# SF32LB57x register map
File version: 1.0
CPU: CM33 r0p1, little endian, MPU, FPU, 3 interrupt priority bits
Registers are 32-bit, read-write, reset 0x0 unless marked. A register's access mark holds for its fields unless they carry their own. Offsets are from the block's base; [hi:lo] are bit positions; {n}, {i} and the like mark numbered series; 'fields as' and 'values as' point back to an identical list.

## USBC
Base 0x50047000
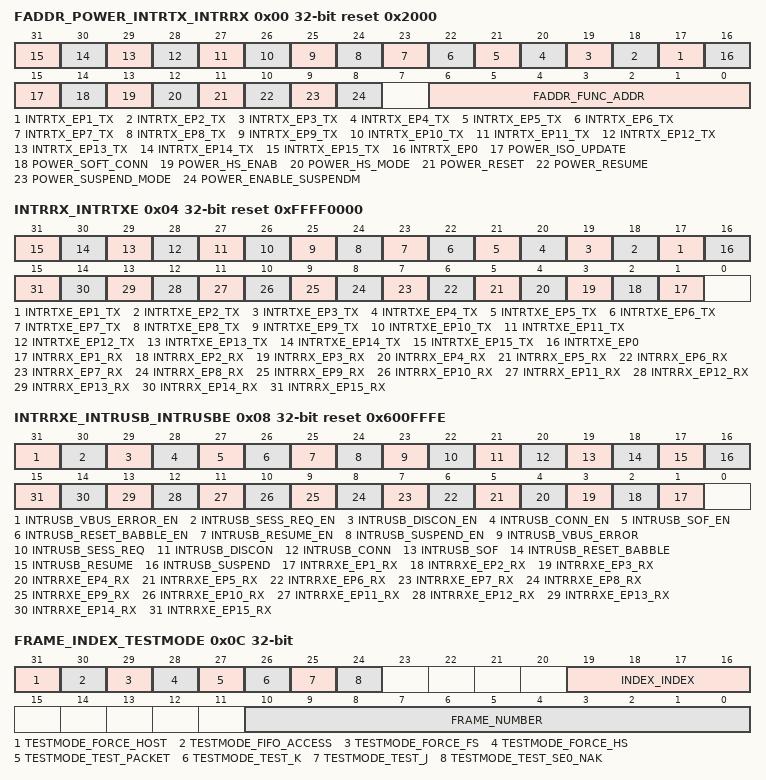
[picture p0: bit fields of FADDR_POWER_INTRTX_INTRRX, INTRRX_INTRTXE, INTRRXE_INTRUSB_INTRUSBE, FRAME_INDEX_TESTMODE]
0x00 FADDR_POWER_INTRTX_INTRRX reset 0x2000
  [n+16] INTRTX_EP{n}_TX (n=1..15) — Tx Endpoint {n} interrupt.
  [16] INTRTX_EP0 — Endpoint 0 interrupt
  [15] POWER_ISO_UPDATE — When set by the CPU, the MUSBHDRC will wait for an SOF token from the time TxPktRdy is set before sending the packet. If an IN token is received before an SOF token, then a zero length data packet will be sent. Note: Only valid in Peripheral Mode. Also, this bit only affects endpoints performing Isochronous transfers.
  [14] POWER_SOFT_CONN — If Soft Connect/Disconnect feature is enabled, then the USB D+/D- lines are enabled when this bit is set by the CPU and tri-stated when this bit is cleared by the CPU. (See Section 5.1) Note: Only valid in Peripheral Mode.
  [13] POWER_HS_ENAB — When set by the CPU, the MUSBHDRC will negotiate for High-speed mode when the device is reset by the hub. If not set, the device will only operate in Full-speed mode.
  [12] POWER_HS_MODE — When set, this read-only bit indicates High-speed mode successfully negotiated during USB reset. In Peripheral Mode, becomes valid when USB reset completes (as indicated by USB reset interrupt). In Host Mode, becomes valid when Reset bit is cleared. Remains valid for the duration of the session. Note: Allowance is made for Tiny-J signaling in determining the transfer speed to select.
  [11] POWER_RESET — This bit is set when Reset signaling is present on the bus. Note: This bit is Read/Write from the CPU in Host Mode but Read-Only in Peripheral Mode.
  [10] POWER_RESUME — Set by the CPU to generate Resume signaling when the function is in Suspend mode. The CPU should clear this bit after 10 ms (a maximum of 15 ms) to end Resume signaling. In Host mode, this bit is also automatically set when Resume signaling from the target is detected while the MUSBHDRC is suspended.
  [9] POWER_SUSPEND_MODE — In Host mode, this bit is set by the CPU to enter Suspend mode. In Peripheral mode, this bit is set on entry into Suspend mode. It is cleared when the CPU reads the interrupt register, or sets the Resume bit above.
  [8] POWER_ENABLE_SUSPENDM — Set by the CPU to enable the SUSPENDM signal.
  [6:0] FADDR_FUNC_ADDR — The function address.
0x04 INTRRX_INTRTXE reset 0xFFFF0000
  [n+16] INTRTXE_EP{n}_TX (n=1..15) — Tx Endpoint {n} interrupt enable.
  [16] INTRTXE_EP0 — Endpoint 0 interrupt enable
  [n] INTRRX_EP{n}_RX (n=1..15) — Rx Endpoint {n} interrupt.
0x08 INTRRXE_INTRUSB_INTRUSBE reset 0x600FFFE
  [31] INTRUSB_VBUS_ERROR_EN — Enable Vbus_Error
  [30] INTRUSB_SESS_REQ_EN — Enable Sess_Req
  [29] INTRUSB_DISCON_EN — Enable Discon
  [28] INTRUSB_CONN_EN — Enable Conn
  [27] INTRUSB_SOF_EN — Enable SOF
  [26] INTRUSB_RESET_BABBLE_EN — Enable Reset_Babble
  [25] INTRUSB_RESUME_EN — Enable Resume
  [24] INTRUSB_SUSPEND_EN — Enable Suspend
  [23] INTRUSB_VBUS_ERROR — Set when VBus drops below the VBus Valid threshold during a session. Only valid when MUSBHDRC is 'A' device.
  [22] INTRUSB_SESS_REQ — Set when Session Request signaling has been detected. Only valid when MUSBHDRC is 'A' device.
  [21] INTRUSB_DISCON — Set in Host mode when a device disconnect is detected. Set in Peripheral mode when a session ends. Valid at all transaction speeds.
  [20] INTRUSB_CONN — Set when a device connection is detected. Only valid in Host mode. Valid at all transaction speeds.
  [19] INTRUSB_SOF — Set when a new frame starts.
  [18] INTRUSB_RESET_BABBLE — Set in Peripheral mode when Reset signaling is detected on the bus. Set in Host mode when babble is detected. Note: Only active after first SOF has been sent.
  [17] INTRUSB_RESUME — Set when Resume signaling is detected on the bus while the MUSBHDRC is in Suspend mode.
  [16] INTRUSB_SUSPEND — Set when Suspend signaling is detected on the bus. Only valid in Peripheral mode.
  [n] INTRRXE_EP{n}_RX (n=1..15) — Rx Endpoint {n} interrupt enable.
0x0C FRAME_INDEX_TESTMODE
  [31] TESTMODE_FORCE_HOST — The CPU sets this bit to instruct the core to enter Host mode when the Session bit is set, regardless of whether it is connected to any peripheral. The state of the CID input, HostDisconnect and LineState signals are ignored. The core will then remain in Host mode until the Session bit is cleared, even if a device is disconnected, and if the Force_Host bit remains set, will re-enter Host mode the next time the Session bit is set. While in this mode, the status of the HOSTDISCON signal from the PHY may be read from bit 7 of the DevCtl register. The operating speed is determined from the Force_HS and Force_FS bits as follows: Force_HS Force_FS Operating Speed 0 0 Low Speed 0 1 Full Speed 1 0 High Speed 1 1 Undefined
  [30] TESTMODE_FIFO_ACCESS — The CPU sets this bit to transfer the packet in the Endpoint 0 Tx FIFO to the Endpoint 0 Rx FIFO. It is cleared automatically.
  [29] TESTMODE_FORCE_FS — The CPU sets this bit either in conjunction with bit 7 above or to force the MUSBHDRC into Fullspeed mode when it receives a USB reset.
  [28] TESTMODE_FORCE_HS — The CPU sets this bit either in conjunction with bit 7 above or to force the MUSBHDRC into Highspeed mode when it receives a USB reset.
  [27] TESTMODE_TEST_PACKET — (High-speed mode) The CPU sets this bit to enter the Test_Packet test mode. In this mode, the MUSBHDRC repetitively transmits on the bus a 53-byte test packet, the form of which is defined in the Universal Serial Bus Specification Revision 2.0, Section 7.1.20 (and in the MUSBHDRC Programmer's Guide). Note: The test packet has a fixed format and must be loaded into the Endpoint 0 FIFO before the test mode is entered.
  [26] TESTMODE_TEST_K — (High-speed mode) The CPU sets this bit to enter the Test_K test mode. In this mode, the MUSBHDRC transmits a continuous K on the bus.
  [25] TESTMODE_TEST_J — (High-speed mode) The CPU sets this bit to enter the Test_J test mode. In this mode, the MUSBHDRC transmits a continuous J on the bus.
  [24] TESTMODE_TEST_SE0_NAK — (High-speed mode) The CPU sets this bit to enter the Test_SE0_NAK test mode. In this mode, the MUSBHDRC remains in High-speed mode but responds to any valid IN token with a NAK.
  [19:16] INDEX_INDEX — Selected Endpoint
  [10:0] FRAME_NUMBER — Frame is a 16-bit read-only register that holds the last received frame number.
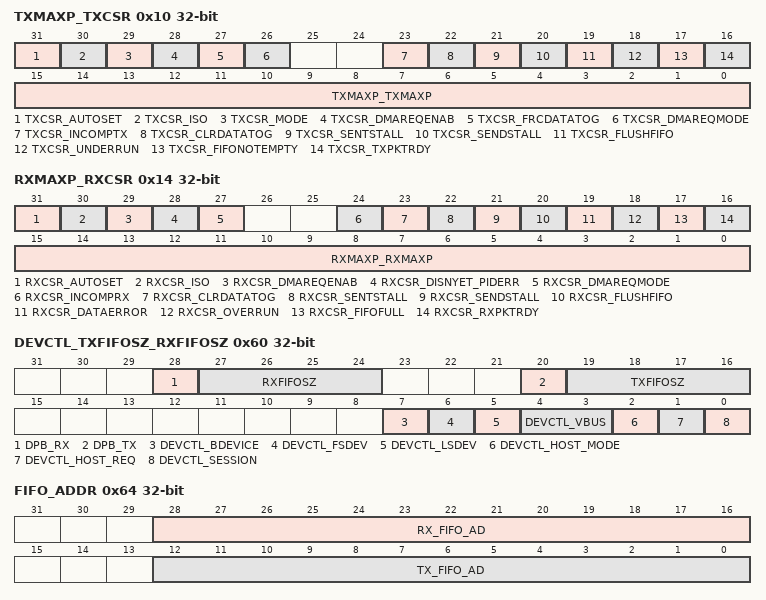
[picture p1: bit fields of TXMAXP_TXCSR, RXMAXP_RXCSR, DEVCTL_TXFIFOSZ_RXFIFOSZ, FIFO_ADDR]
0x10 TXMAXP_TXCSR
  [31] TXCSR_AUTOSET — If the CPU sets this bit, TxPktRdy will be automatically set when data of the maximum packet size (value in TxMaxP) is loaded into the Tx FIFO. If a packet of less than the maximum packet size is loaded, then TxPktRdy will have to be set manually. Note: Should not be set for either high-bandwidth Isochronous endpoints or high-bandwidth Interrupt endpoints.
  [30] TXCSR_ISO — The CPU sets this bit to enable the Tx endpoint for Isochronous transfers, and clears it to enable the Tx endpoint for Bulk or Interrupt transfers. Note: This bit only has any effect in Peripheral mode. In Host mode, it always returns zero.
  [29] TXCSR_MODE — The CPU sets this bit to enable the endpoint direction as Tx, and clears it to enable the endpoint direction as Rx. Note: This bit only has any effect where the same endpoint FIFO is used for both Tx and Rx transactions.
  [28] TXCSR_DMAREQENAB — The CPU sets this bit to enable the DMA request for the Tx endpoint.
  [27] TXCSR_FRCDATATOG — The CPU sets this bit to force the endpoint data toggle to switch and the data packet to be cleared from the FIFO, regardless of whether an ACK was received. This can be used by Interrupt Tx endpoints that are used to communicate rate feedback for Isochronous endpoints.
  [26] TXCSR_DMAREQMODE — The CPU sets this bit to select DMA Mode 1 and clears this bit to select DMA Mode 0. Note: This bit must not be cleared either before or in the same cycle as the above DMAReqEnab bit is cleared.
  [23] TXCSR_INCOMPTX — When the endpoint is being used for high-bandwidth Isochronous/Interrupt transfers, this bit is set to indicate where a large packet has been split into 2 or 3 packets for transmission but insufficient IN tokens have been received to send all the parts. Note: In anything other than a high bandwidth transfer, this bit will always return 0.
  [22] TXCSR_CLRDATATOG — The CPU writes a 1 to this bit to reset the endpoint data toggle to 0.
  [21] TXCSR_SENTSTALL — This bit is set when a STALL handshake is transmitted. The FIFO is flushed and the TxPktRdy bit is cleared (see below). The CPU should clear this bit.
  [20] TXCSR_SENDSTALL — The CPU writes a 1 to this bit to issue a STALL handshake to an IN token. The CPU clears this bit to terminate the stall condition. Note::(i) The FIFO should be flushed before SendStall is set. (ii) This bit has no effect where the endpoint is being used for Isochronous transfers.
  [19] TXCSR_FLUSHFIFO — The CPU writes a 1 to this bit to flush the latest packet from the endpoint Tx FIFO. The FIFO pointer is reset, the TxPktRdy bit (below) is cleared and an interrupt is generated. May be set simultaneously with TxPktRdy to abort the packet that is currently being loaded into the FIFO. Note: FlushFIFO should only be used when TxPktRdy is set. At other times, it may cause data to be corrupted. Also note that, if the FIFO is double-buffered, FlushFIFO may need to be set twice to completely clear the FIFO.
  [18] TXCSR_UNDERRUN — The USB sets this bit if an IN token is received when the TxPktRdy bit not set. The CPU should clear this bit.
  [17] TXCSR_FIFONOTEMPTY — Control Status register for peripheral Tx endpoint. (Index register set to select Endpoints 1 – 15) Control Status register for Endpoint 0.(Index register set to select Endpoint 0)
  [16] TXCSR_TXPKTRDY — Control Status register for peripheral Tx endpoint. (Index register set to select Endpoints 1 – 15) Control Status register for Endpoint 0.(Index register set to select Endpoint 0)
  [15:0] TXMAXP_TXMAXP — Maximum packet size for peripheral Tx endpoint. (Index register set to select Endpoints 1 – 15 only)
0x14 RXMAXP_RXCSR
  [31] RXCSR_AUTOSET — If the CPU sets this bit then the RxPktRdy bit will be automatically cleared when a packet of RxMaxP bytes has been unloaded from the Rx FIFO. When packets of less than the maximum packet size are unloaded, RxPktRdy will have to be cleared manually. Note: Should not be set for high bandwidth Isochronous endpoints.
  [30] RXCSR_ISO — The CPU sets this bit to enable the Rx endpoint for Isochronous transfers, and clears it to enable the Rx endpoint for Bulk or Interrupt transfers. Note: This bit only has any effect in Peripheral mode. In Host mode, it always returns zero.
  [29] RXCSR_DMAREQENAB — The CPU sets this bit to enable the DMA request for the Rx endpoint.
  [28] RXCSR_DISNYET_PIDERR — Bulk/Interrupt Transactions: The CPU sets this bit to disable the sending of NYET handshakes. When set, all successfully received Rx packets are ACK'd including at the point at which the FIFO becomes full. Note: This bit only has any effect in High-speed mode, in which mode it should be set for all Interrupt endpoints. ISO Transactions: The core sets this bit to indicate a PID error in the received packet.
  [27] RXCSR_DMAREQMODE — The CPU sets this bit to select DMA Mode 1 and clears this bit to select DMA Mode 0. Note: This bit should not be cleared in the same cycle as RxPktRdy is cleared. endpoints that are used to communicate rate feedback for Isochronous endpoints.
  [24] RXCSR_INCOMPRX — This bit is set in a high-bandwidth Isochronous/Interrupt transfer if the packet in the Rx FIFO is incomplete because parts of the data were not received. It is cleared when RxPktRdy is cleared. Note: In anything other than a high-bandwidth transfer, this bit will always return 0.
  [23] RXCSR_CLRDATATOG — The CPU writes a 1 to this bit to reset the endpoint data toggle to 0.
  [22] RXCSR_SENTSTALL — This bit is set when a STALL handshake is transmitted. The FIFO is flushed and the TxPktRdy bit is cleared (see below). The CPU should clear this bit.
  [21] RXCSR_SENDSTALL — The CPU writes a 1 to this bit to issue a STALL handshake to an IN token. The CPU clears this bit to terminate the stall condition. Note::(i) The FIFO should be flushed before SendStall is set. (ii) This bit has no effect where the endpoint is being used for Isochronous transfers.
  [20] RXCSR_FLUSHFIFO — The CPU writes a 1 to this bit to flush the next packet to be read from the endpoint Rx FIFO. The FIFO pointer is reset and the RxPktRdy bit (below) is cleared. Note: FlushFIFO should only be used when RxPktRdy is set. At other times, it may cause data to be corrupted. Also note that, if the FIFO is double-buffered, FlushFIFO may need to be set twice to completely clear the FIFO..
  [19] RXCSR_DATAERROR — This bit is set when RxPktRdy is set if the data packet has a CRC or bit-stuff error. It is cleared when RxPktRdy is cleared. Note: This bit is only valid when the endpoint is operating in ISO mode. In Bulk mode, it always returns zero.
  [18] RXCSR_OVERRUN — This bit is set if an OUT packet cannot be loaded into the Rx FIFO. The CPU should clear this bit. Note: This bit is only valid when the endpoint is operating in ISO mode. In Bulk mode, it always returns zero.
  [17] RXCSR_FIFOFULL — This bit is set when no more packets can be loaded into the Rx FIFO.
  [16] RXCSR_RXPKTRDY — CThis bit is set when a data packet has been received. The CPU should clear this bit when the packet has been unloaded from the Rx FIFO. An interrupt is generated when the bit is set.
  [15:0] RXMAXP_RXMAXP — Maximum packet size for peripheral Rx endpoint. (Index register set to select Endpoints 1 – 15 only)
0x18 COUNT
  [15:0] COUNT0_RXCOUNT — Number of bytes in peripheral Rx endpoint FIFO. (Index register set to select Endpoints 1 – 15) Number of received bytes in Endpoint 0 FIFO. (Index register set to select Endpoint 0)
0x1C FIFOSIZE_CFG
  [31:24] FIFOSIZE_CFG — Returns the configured size of the selected Rx FIFO and Tx FIFOs (Endpoints 1 – 15 only). Returns details of core configuration. (Index register set to select Endpoint 0.)
{0x20+4i} FIFO{i} (i=0..15)
  [31:0] FIFO — This address range provides 16 addresses for CPU access to the FIFOs for each endpoint. Writing to these addresses loads data into the TxFIFO for the corresponding endpoint. Reading from these addresses unloads data from the RxFIFO for the corresponding endpoint.Transfers to and from FIFOs may be 8-bit, 16-bit or 32-bit as required, and any combination of access is allowed provided the data accessed is contiguous.
0x60 DEVCTL_TXFIFOSZ_RXFIFOSZ
  [28] DPB_RX — Defines whether double-packet buffering supported. When '1', double-packet buffering is supported. When '0', only single-packet buffering is supported.
  [27:24] RXFIFOSZ — Rx Endpoint FIFO size,The option of setting FIFO sizes dynamically only applies to Endpoints 1…15. 9.2.2 and 12) SZ[3:0] Packet Size (Bytes) 0 0 0 0 8 0 0 0 1 16 0 0 1 0 32 0 0 1 1 64 0 1 0 0 128 0 1 0 1 256 0 1 1 0 512 0 1 1 1 1024 1 0 0 0 2048 1 0 0 1 4096 D3 – D0 SZ[3:0] If DPB = 0, the FIFO will also be this size; if DPB = 1, the FIFO will be twice this size.
  [20] DPB_TX — Defines whether double-packet buffering supported. When '1', double-packet buffering is supported. When '0', only single-packet buffering is supported.
  [19:16] TXFIFOSZ — Tx Endpoint FIFO size,The option of setting FIFO sizes dynamically only applies to Endpoints 1…15. 9.2.2 and 12) SZ[3:0] Packet Size (Bytes) 0 0 0 0 8 0 0 0 1 16 0 0 1 0 32 0 0 1 1 64 0 1 0 0 128 0 1 0 1 256 0 1 1 0 512 0 1 1 1 1024 1 0 0 0 2048 1 0 0 1 4096 D3 – D0 SZ[3:0] If DPB = 0, the FIFO will also be this size; if DPB = 1, the FIFO will be twice this size.
  [7] DEVCTL_BDEVICE — This Read-only bit indicates whether the MUSBHDRC is operating as the 'A' device or the 'B' device. 0 ⇒ 'A' device; 1 ⇒ 'B' device. Only valid while a session is in progress. Note: If the core is in Force_Host mode (i.e. a session has been started with Testmode.D7 = 1), this bit will indicate the state of the HOSTDISCON input signal from the PHY.
  [6] DEVCTL_FSDEV — This Read-only bit is set when a full-speed or high-speed device has been detected being connected to the port. (High-speed devices are distinguished from full-speed by checking for high-speed chirps when the device is reset.) Only valid in Host mode.
  [5] DEVCTL_LSDEV — This Read-only bit is set when a low-speed device has been detected being connected to the port. Only valid in Host mode.
  [4:3] DEVCTL_VBUS — These Read-only bits encode the current VBus level as follows: D4 D3 Meaning 0 0 Below SessionEnd 0 1 Above SessionEnd, below AValid 1 0 Above AValid, below VBusValid 1 1 Above VBusValid
  [2] DEVCTL_HOST_MODE — This Read-only bit is set when the MUSBHDRC is acting as a Host.
  [1] DEVCTL_HOST_REQ — When set, the MUSBHDRC will initiate the Host Negotiation when Suspend mode is entered. It is cleared when Host Negotiation is completed. See Section 15. ('B' device only)
  [0] DEVCTL_SESSION — When operating as an 'A' device, this bit is set or cleared by the CPU to start or end a session. When operating as a 'B' device, this bit is set/cleared by the MUSBHDRC when a session starts/ends. It is also set by the CPU to initiate the Session Request Protocol, or cleared by the CPU when in Suspend mode to perform a software disconnect. Note: Clearing this bit when the core is not suspended will result in undefined behavior.
0x64 FIFO_ADDR
  [28:16] RX_FIFO_AD — Start address of the endpoint FIFO in units of 8 bytes as follows: AD[12:0] Start Address 0 0 0 0 0000 0 0 0 1 0008 0 0 0 2 0010 … … 1 F F F FFF8
  [12:0] TX_FIFO_AD — Start address of the endpoint FIFO in units of 8 bytes as follows: AD[12:0] Start Address 0 0 0 0 0000 0 0 0 1 0008 0 0 0 2 0010 … … 1 F F F FFF8
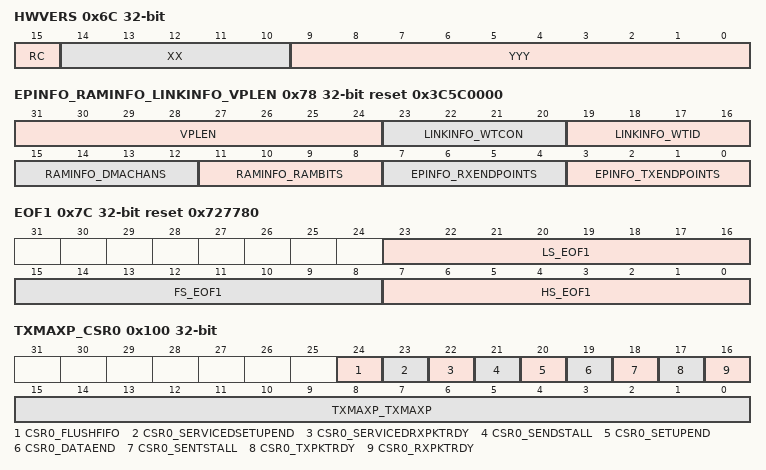
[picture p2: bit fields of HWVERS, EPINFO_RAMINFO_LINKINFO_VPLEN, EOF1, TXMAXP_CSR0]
0x6C HWVERS
  [15] RC — Set to '1' if RTL used from a Release Candidate rather than from a full release of the core.
  [14:10] XX — Major Version Number (Range 0 – 31).
  [9:0] YYY — Minor Version Number (Range 0 – 999).
0x78 EPINFO_RAMINFO_LINKINFO_VPLEN reset 0x3C5C0000
  [31:24] VPLEN — Sets the duration of the VBus pulsing charge in units of 546.1 μs. (The default setting corresponds to 32.77ms.)
  [23:20] LINKINFO_WTCON — Sets the wait to be applied to allow for the user's connect/disconnect filter in units of 533.3ns. (The default setting corresponds to 2.667μs.)
  [19:16] LINKINFO_WTID — Sets the delay to be applied from IDPULLUP being asserted to IDDIG being considered valid in units of 4.369ms. (The default setting corresponds to 52.43ms.)
  [15:12] RAMINFO_DMACHANS — The number of DMA channels implemented in the design.
  [11:8] RAMINFO_RAMBITS — The width of the RAM address bus – 1.
  [7:4] EPINFO_RXENDPOINTS — The number of Rx endpoints implemented in the design.
  [3:0] EPINFO_TXENDPOINTS — The number of Tx endpoints implemented in the design.
0x7C EOF1 reset 0x727780
  [23:16] LS_EOF1 — Sets for Low-speed transactions the time before EOF to stop beginning new transactions, in units of 1.067μs. (The default setting corresponds to 121.6μs.)
  [15:8] FS_EOF1 — Sets for Full-speed transactions the time before EOF to stop beginning new transactions, in units of 533.3ns. (The default setting corresponds to 63.46μs.)
  [7:0] HS_EOF1 — Sets for High-speed transactions the time before EOF to stop beginning new transactions, in units of 133.3ns. (The default setting corresponds to 17.07μs.)
0x100 TXMAXP_CSR0
  [24] CSR0_FLUSHFIFO — The CPU writes a 1 to this bit to flush the next packet to be transmitted/read from the Endpoint 0 FIFO. The FIFO pointer is reset and the TxPktRdy/RxPktRdy bit (below) is cleared. Note: FlushFIFO should only be used when TxPktRdy/RxPktRdy is set. At other times, it may cause data to be corrupted.
  [23] CSR0_SERVICEDSETUPEND — The CPU writes a 1 to this bit to clear the SetupEnd bit. It is cleared automatically.
  [22] CSR0_SERVICEDRXPKTRDY — The CPU writes a 1 to this bit to clear the RxPktRdy bit. It is cleared automatically.
  [21] CSR0_SENDSTALL — The CPU writes a 1 to this bit to terminate the current transaction. The STALL handshake will be transmitted and then this bit will be cleared automatically. Note: The FIFO should be flushed before SendStall is set.
  [20] CSR0_SETUPEND — This bit will be set when a control transaction ends before the DataEnd bit has been set. An interrupt will be generated and the FIFO flushed at this time. The bit is cleared by the CPU writing a 1 to the ServicedSetupEnd bit.
  [19] CSR0_DATAEND — The CPU sets this bit: 1. When setting TxPktRdy for the last data packet. 2. When clearing RxPktRdy after unloading the last data packet. 3. When setting TxPktRdy for a zero length data packet. It is cleared automatically.
  [18] CSR0_SENTSTALL — The USB sets this bit if an IN token is received when the TxPktRdy bit not set. The CPU should clear this bit.
  [17] CSR0_TXPKTRDY — The CPU sets this bit after loading a data packet into the FIFO. It is cleared automatically when the data packet has been transmitted. An interrupt is generated (if enabled) when the bit is cleared.
  [16] CSR0_RXPKTRDY — This bit is set when a data packet has been received. An interrupt is generated when this bit is set. The CPU clears this bit by setting the ServicedRxPktRdy bit.
  [15:0] TXMAXP_TXMAXP — Maximum packet size for peripheral Tx endpoint. (Index register set to select Endpoints 1 – 15 only)
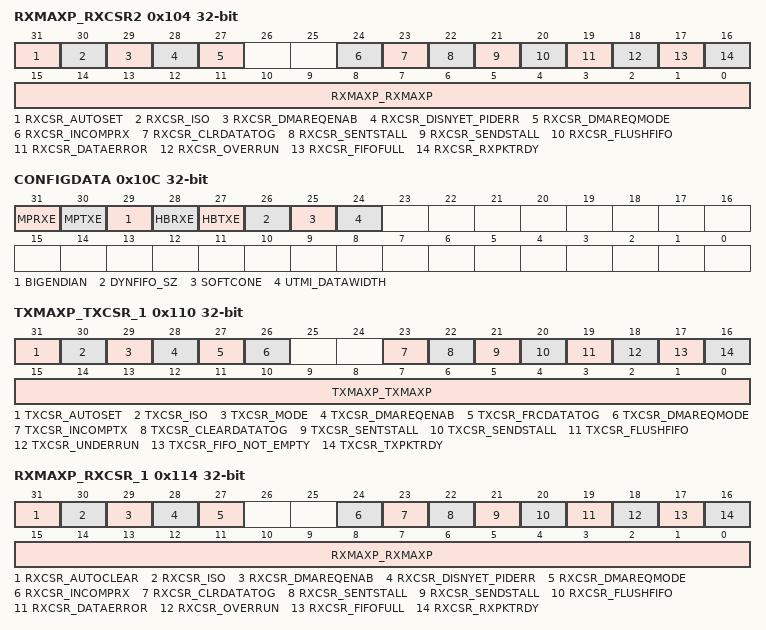
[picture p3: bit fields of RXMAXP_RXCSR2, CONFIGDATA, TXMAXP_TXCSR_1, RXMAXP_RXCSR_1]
0x104 RXMAXP_RXCSR2 — RXMAXP_RXCSR
  fields as RXMAXP_RXCSR
0x108 COUNT0 — COUNT
  [6:0] COUNT0 — Number of received bytes in Endpoint 0 FIFO. (Index register set to select Endpoint 0)
0x10C CONFIGDATA — FIFOSIZE_CFG
  [31] MPRXE — When set to '1', automatic amalgamation of bulk packets is selected (see Section 9)
  [30] MPTXE — When set to '1', automatic splitting of bulk packets is selected (see Section 9)
  [29] BIGENDIAN — When set to '1' indicates Big Endian ordering is selected.
  [28] HBRXE — When set to '1' indicates High-bandwidth Rx ISO Endpoint Support selected.
  [27] HBTXE — When set to '1' indicates High-bandwidth Tx ISO Endpoint Support selected.
  [26] DYNFIFO_SZ — When set to '1' indicates Dynamic FIFO Sizing option selected.
  [25] SOFTCONE — When set to '1' indicates Soft Connect/Disconnect option selected.
  [24] UTMI_DATAWIDTH — Indicates selected UTMI+ data width. 0 ⇒ 8 bits; 1 ⇒ 16 bits.
0x110 TXMAXP_TXCSR_1 — TXMAXP_CSR1
  [31] TXCSR_AUTOSET — If the CPU sets this bit, TxPktRdy will be automatically set when data of the maximum packet size (value in TxMaxP) is loaded into the Tx FIFO. If a packet of less than the maximum packet size is loaded, then TxPktRdy will have to be set manually. Note: Should not be set for either high-bandwidth Isochronous endpoints or high-bandwidth Interrupt endpoints.
  [30] TXCSR_ISO — The CPU sets this bit to enable the Tx endpoint for Isochronous transfers, and clears it to enable the Tx endpoint for Bulk or Interrupt transfers. Note: This bit only has any effect in Peripheral mode. In Host mode, it always returns zero.
  [29] TXCSR_MODE — The CPU sets this bit to enable the endpoint direction as Tx, and clears it to enable the endpoint direction as Rx. Note: This bit only has any effect where the same endpoint FIFO is used for both Tx and Rx transactions.
  [28] TXCSR_DMAREQENAB — The CPU sets this bit to enable the DMA request for the Tx endpoint.
  [27] TXCSR_FRCDATATOG — The CPU sets this bit to force the endpoint data toggle to switch and the data packet to be cleared from the FIFO, regardless of whether an ACK was received. This can be used by Interrupt Tx endpoints that are used to communicate rate feedback for Isochronous endpoints.
  [26] TXCSR_DMAREQMODE — The CPU sets this bit to select DMA Mode 1 and clears this bit to select DMA Mode 0. Note: This bit must not be cleared either before or in the same cycle as the above DMAReqEnab bit is cleared
  [23] TXCSR_INCOMPTX — When the endpoint is being used for high-bandwidth Isochronous/Interrupt transfers, this bit is set to indicate where a large packet has been split into 2 or 3 packets for transmission but insufficient IN tokens have been received to send all the parts. Note: In anything other than a high bandwidth transfer, this bit will always return 0.
  [22] TXCSR_CLEARDATATOG — The CPU writes a 1 to this bit to reset the endpoint data toggle to 0.
  [21] TXCSR_SENTSTALL — This bit is set when a STALL handshake is transmitted. The FIFO is flushed and the TxPktRdy bit is cleared (see below). The CPU should clear this bit.
  [20] TXCSR_SENDSTALL — The CPU writes a 1 to this bit to issue a STALL handshake to an IN token. The CPU clears this bit to terminate the stall condition. Note::(i) The FIFO should be flushed before SendStall is set. (ii) This bit has no effect where the endpoint is being used for Isochronous transfers. An interrupt will be generated and the FIFO flushed at this time. The bit is cleared by the CPU writing a 1 to the ServicedSetupEnd bit.
  [19] TXCSR_FLUSHFIFO — The CPU writes a 1 to this bit to flush the latest packet from the endpoint Tx FIFO. The FIFO pointer is reset, the TxPktRdy bit (below) is cleared and an interrupt is generated. May be set simultaneously with TxPktRdy to abort the packet that is currently being loaded into the FIFO. Note: FlushFIFO should only be used when TxPktRdy is set. At other times, it may cause data to be corrupted. Also note that, if the FIFO is double-buffered, FlushFIFO may need to be set twice to completely clear the FIFO.
  [18] TXCSR_UNDERRUN — The USB sets this bit if an IN token is received when the TxPktRdy bit not set. The CPU should clear this bit.
  [17] TXCSR_FIFO_NOT_EMPTY — The USB sets this bit when there is at least 1 packet in the Tx FIFO.
  [16] TXCSR_TXPKTRDY — The CPU sets this bit after loading a data packet into the FIFO. It is cleared automatically when a data packet has been transmitted. An interrupt is also generated at this point (if enabled). TxPktRdy is also automatically cleared prior to loading a second packet into a double-buffered FIFO. is set. The CPU clears this bit by setting the ServicedRxPktRdy bit.
  [15:0] TXMAXP_TXMAXP — Maximum packet size for peripheral Tx endpoint. (Index register set to select Endpoints 1 – 15 only)
0x114 RXMAXP_RXCSR_1 — RXMAXP_RXCSR
  [31] RXCSR_AUTOCLEAR — If the CPU sets this bit then the RxPktRdy bit will be automatically cleared when a packet of RxMaxP bytes has been unloaded from the Rx FIFO. When packets of less than the maximum packet size are unloaded, RxPktRdy will have to be cleared manually. Note: Should not be set for high bandwidth Isochronous endpoints.
  [30] RXCSR_ISO — The CPU sets this bit to enable the Rx endpoint for Isochronous transfers, and clears it to enable the Rx endpoint for Bulk or Interrupt transfers. Note: This bit only has any effect in Peripheral mode. In Host mode, it always returns zero.
  [29] RXCSR_DMAREQENAB — The CPU sets this bit to enable the DMA request for the Rx endpoint.
  [28] RXCSR_DISNYET_PIDERR — Bulk/Interrupt Transactions: The CPU sets this bit to disable the sending of NYET handshakes. When set, all successfully received Rx packets are ACK'd including at the point at which the FIFO becomes full. Note: This bit only has any effect in High-speed mode, in which mode it should be set for all Interrupt endpoints. ISO Transactions: The core sets this bit to indicate a PID error in the received packet.
  [27] RXCSR_DMAREQMODE — The CPU sets this bit to select DMA Mode 1 and clears this bit to select DMA Mode 0. Note: This bit should not be cleared in the same cycle as RxPktRdy is cleared. endpoints that are used to communicate rate feedback for Isochronous endpoints.
  [24] RXCSR_INCOMPRX — This bit is set in a high-bandwidth Isochronous/Interrupt transfer if the packet in the Rx FIFO is incomplete because parts of the data were not received. It is cleared when RxPktRdy is cleared. Note: In anything other than a high-bandwidth transfer, this bit will always return 0.
  [23] RXCSR_CLRDATATOG — The CPU writes a 1 to this bit to reset the endpoint data toggle to 0.
  [22] RXCSR_SENTSTALL — This bit is set when a STALL handshake is transmitted. The FIFO is flushed and the TxPktRdy bit is cleared (see below). The CPU should clear this bit.
  [21] RXCSR_SENDSTALL — The CPU writes a 1 to this bit to issue a STALL handshake to an IN token. The CPU clears this bit to terminate the stall condition. Note::(i) The FIFO should be flushed before SendStall is set. (ii) This bit has no effect where the endpoint is being used for Isochronous transfers.
  [20] RXCSR_FLUSHFIFO — The CPU writes a 1 to this bit to flush the next packet to be read from the endpoint Rx FIFO. The FIFO pointer is reset and the RxPktRdy bit (below) is cleared. Note: FlushFIFO should only be used when RxPktRdy is set. At other times, it may cause data to be corrupted. Also note that, if the FIFO is double-buffered, FlushFIFO may need to be set twice to completely clear the FIFO..
  [19] RXCSR_DATAERROR — This bit is set when RxPktRdy is set if the data packet has a CRC or bit-stuff error. It is cleared when RxPktRdy is cleared. Note: This bit is only valid when the endpoint is operating in ISO mode. In Bulk mode, it always returns zero.
  [18] RXCSR_OVERRUN — This bit is set if an OUT packet cannot be loaded into the Rx FIFO. The CPU should clear this bit. Note: This bit is only valid when the endpoint is operating in ISO mode. In Bulk mode, it always returns zero.
  [17] RXCSR_FIFOFULL — This bit is set when no more packets can be loaded into the Rx FIFO.
  [16] RXCSR_RXPKTRDY — CThis bit is set when a data packet has been received. The CPU should clear this bit when the packet has been unloaded from the Rx FIFO. An interrupt is generated when the bit is set.
  [15:0] RXMAXP_RXMAXP — Maximum packet size for peripheral Rx endpoint. (Index register set to select Endpoints 1 – 15 only)
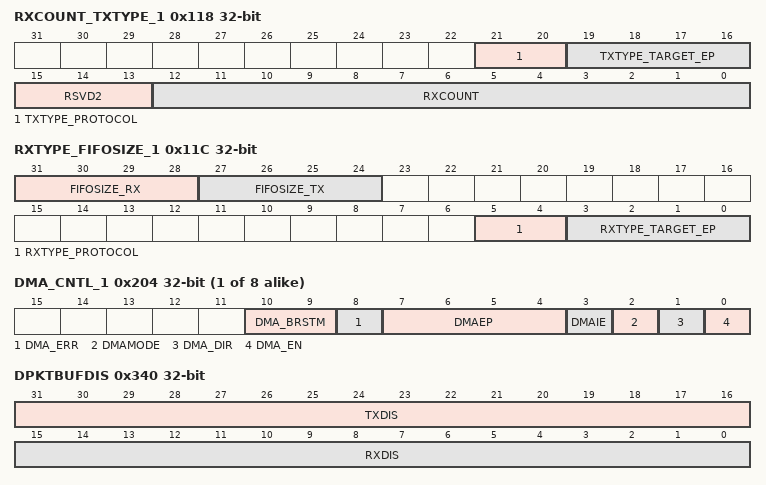
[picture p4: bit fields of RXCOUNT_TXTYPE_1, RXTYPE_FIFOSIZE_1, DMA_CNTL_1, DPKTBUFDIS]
0x118 RXCOUNT_TXTYPE_1 — RXCOUNT_TXType
  [21:20] TXTYPE_PROTOCOL — The CPU should set this to select the required protocol for the Tx endpoint: 00: Illegal 01: Isochronous 10: Bulk 11: Interrupt
  [19:16] TXTYPE_TARGET_EP — The CPU should set this value to the endpoint number contained in the Tx endpoint descriptor
  [15:13] RSVD2 — returned to the MUSBHDRC during device enumeration.
  [12:0] RXCOUNT — RxCount is a 13-bit read-only register that holds the number of received data bytes in the packet currently in line to be read from the Rx FIFO. If the packet was transmitted as multiple bulk packets, the number given will be for the combined packet. Note: The value returned changes as the FIFO is unloaded and is only valid while RxPktRdy (RxCSR.D0) is set.
0x11C RXTYPE_FIFOSIZE_1 — RXType_Fifo Size
  [31:28] FIFOSIZE_RX — FIFOSize is an 8-bit Read-Only register that returns the sizes of the FIFOs associated with the selected additional Tx/Rx endpoints. The lower nibble encodes the size of the selected Tx endpoint FIFO; the upper nibble encodes the size of the selected Rx endpoint FIFO. Values of 3 – 13 correspond to a FIFO size of 2n bytes (8 – 8192 bytes). If an endpoint has not been configured, a value of 0 will be displayed. Where the Tx and Rx endpoints share the same FIFO, the Rx FIFO size will be encoded as 0xF
  [27:24] FIFOSIZE_TX — FIFOSize is an 8-bit Read-Only register that returns the sizes of the FIFOs associated with the selected additional Tx/Rx endpoints. The lower nibble encodes the size of the selected Tx endpoint FIFO; the upper nibble encodes the size of the selected Rx endpoint FIFO. Values of 3 – 13 correspond to a FIFO size of 2n bytes (8 – 8192 bytes). If an endpoint has not been configured, a value of 0 will be displayed. Where the Tx and Rx endpoints share the same FIFO, the Rx FIFO size will be encoded as 0xF
  [5:4] RXTYPE_PROTOCOL — The CPU should set this to select the required protocol for the Rx endpoint: 00: Illegal 01: Isochronous 10: Bulk 11: Interrupt
  [3:0] RXTYPE_TARGET_EP — The CPU should set this value to the endpoint number contained in the Rx endpoint descriptor
0x200 DMA_INTR
  [7:0] DMA_INTR — Channel 1~8 DMA Interrupt
{0x1F4+0x10*i} DMA_CNTL_{i} (i=1..8)
  [10:9] DMA_BRSTM — Burst Mode 00 = Burst Mode 0 : Bursts of unspecified length 01 = Burst Mode 1 : INCR4 or unspecified length 10 = Burst Mode 2 : INCR8, INCR4 or unspecified length 11 = Burst Mode 3 : INCR16, INCR8, INCR4 or unspecified length
  [8] DMA_ERR — Bus Error Bit. Indicates that a bus error has been observed on the input AHB_HRESPM[1:0]. This bit is cleared by software.
  [7:4] DMAEP — The endpoint number this channel is assigned to.
  [3] DMAIE — DMA Interrupt Enable.
  [2] DMAMODE — This bit selects the DMA Transfer Mode. 0 = DMA Mode0 Transfer 1 = DMA Mode1 Transfer
  [1] DMA_DIR — This bit selects the DMA Transfer Direction. 0 = DMA Write (RX Endpoint) 1 = DMa Read (TX Endpoint)
  [0] DMA_EN — This bit enables the DMA transfer and will cause the transfer to begin.
{0x1F8+0x10*i} DMA_ADDR_{i} (i=1..8)
  [31:0] DMA_ADDR — The DMA memory address. Note that the initial memory address written to this register must have a value such that it’s modulo 4 value is equal to 0. That is, DMA_ADDR[1:0] must be equal to 2’b00. The lower two bits of this register are read only and cannot be set by software.
{0x1FC+0x10*i} DMA_COUNT_{i} (i=1..8)
  [31:0] DMA_COUNT — The DMA memory address for the corresponding DMA channel. Note: If DMA is enabled with a count of 0, the bus will not be requested and a DMA interrupt will be generated.
0x340 DPKTBUFDIS
  [31:16] TXDIS, [15:0] RXDIS
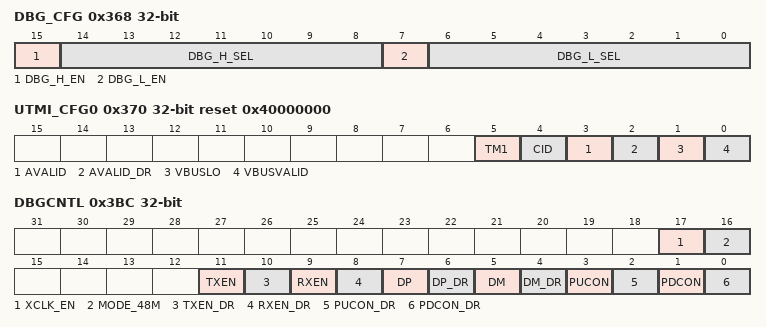
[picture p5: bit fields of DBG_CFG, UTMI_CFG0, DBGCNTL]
0x368 DBG_CFG
  [15] DBG_H_EN, [14:8] DBG_H_SEL, [7] DBG_L_EN, [6:0] DBG_L_SEL
0x370 UTMI_CFG0 reset 0x40000000
  [5] TM1 — test mode
  [4] CID
  [3] AVALID
  [2] AVALID_DR
  [1] VBUSLO
  [0] VBUSVALID
0x3BC DBGCNTL
  [17] XCLK_EN, [16] MODE_48M, [11] TXEN, [10] TXEN_DR, [9] RXEN, [8] RXEN_DR, [7] DP, [6] DP_DR, [5] DM, [4] DM_DR, [3] PUCON, [2] PUCON_DR, [1] PDCON, [0] PDCON_DR
0x3C0 FSLPCFG
  [0] LP_MODE
0x3C4 FSLPTX
  [31:0] LP_TXDATA
0x3C8 FSLPRX
  [31:0] LP_RXDATA
